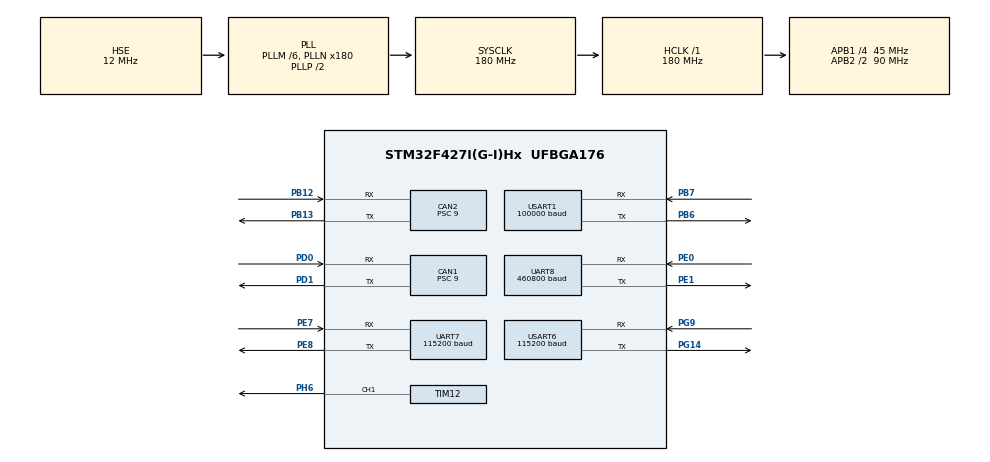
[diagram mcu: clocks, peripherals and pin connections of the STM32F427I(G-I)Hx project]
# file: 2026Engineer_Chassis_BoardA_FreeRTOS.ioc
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CAN1.BS1=CAN_BS1_2TQ
CAN1.BS2=CAN_BS2_2TQ
CAN1.CalculateBaudRate=1000000
CAN1.CalculateTimeBit=1000
CAN1.CalculateTimeQuantum=200.0
CAN1.NART=ENABLE
CAN1.Prescaler=9
CAN2.BS1=CAN_BS1_2TQ
CAN2.BS2=CAN_BS2_2TQ
CAN2.CalculateBaudRate=1000000
CAN2.CalculateTimeBit=1000
CAN2.CalculateTimeQuantum=200.0
CAN2.Prescaler=9
Dma.Request0=USART1_RX
Dma.Request1=USART1_TX
Dma.Request2=USART6_RX
Dma.Request3=USART6_TX
Dma.Request4=UART7_RX
Dma.Request5=UART7_TX
Dma.UART7_RX.4.Direction=DMA_PERIPH_TO_MEMORY
Dma.UART7_RX.4.FIFOMode=DMA_FIFOMODE_DISABLE
Dma.UART7_RX.4.Instance=DMA1_Stream3
Dma.UART7_RX.4.MemDataAlignment=DMA_MDATAALIGN_BYTE
Dma.UART7_RX.4.MemInc=DMA_MINC_ENABLE
Dma.UART7_RX.4.Mode=DMA_NORMAL
Dma.UART7_RX.4.PeriphDataAlignment=DMA_PDATAALIGN_BYTE
Dma.UART7_RX.4.PeriphInc=DMA_PINC_DISABLE
Dma.UART7_RX.4.Priority=DMA_PRIORITY_LOW
Dma.UART7_TX.5.Direction=DMA_MEMORY_TO_PERIPH
Dma.UART7_TX.5.FIFOMode=DMA_FIFOMODE_DISABLE
Dma.UART7_TX.5.Instance=DMA1_Stream1
Dma.UART7_TX.5.MemDataAlignment=DMA_MDATAALIGN_BYTE
Dma.UART7_TX.5.MemInc=DMA_MINC_ENABLE
Dma.UART7_TX.5.Mode=DMA_NORMAL
Dma.UART7_TX.5.PeriphDataAlignment=DMA_PDATAALIGN_BYTE
Dma.UART7_TX.5.PeriphInc=DMA_PINC_DISABLE
Dma.UART7_TX.5.Priority=DMA_PRIORITY_LOW
Dma.USART1_RX.0.Direction=DMA_PERIPH_TO_MEMORY
Dma.USART1_RX.0.FIFOMode=DMA_FIFOMODE_DISABLE
Dma.USART1_RX.0.Instance=DMA2_Stream2
Dma.USART1_RX.0.MemDataAlignment=DMA_MDATAALIGN_BYTE
Dma.USART1_RX.0.MemInc=DMA_MINC_ENABLE
Dma.USART1_RX.0.Mode=DMA_NORMAL
Dma.USART1_RX.0.PeriphDataAlignment=DMA_PDATAALIGN_BYTE
Dma.USART1_RX.0.PeriphInc=DMA_PINC_DISABLE
Dma.USART1_RX.0.Priority=DMA_PRIORITY_LOW
Dma.USART1_TX.1.Direction=DMA_MEMORY_TO_PERIPH
Dma.USART1_TX.1.FIFOMode=DMA_FIFOMODE_DISABLE
Dma.USART1_TX.1.Instance=DMA2_Stream7
Dma.USART1_TX.1.MemDataAlignment=DMA_MDATAALIGN_BYTE
Dma.USART1_TX.1.MemInc=DMA_MINC_ENABLE
Dma.USART1_TX.1.Mode=DMA_NORMAL
Dma.USART1_TX.1.PeriphDataAlignment=DMA_PDATAALIGN_BYTE
Dma.USART1_TX.1.PeriphInc=DMA_PINC_DISABLE
Dma.USART1_TX.1.Priority=DMA_PRIORITY_LOW
Dma.USART6_RX.2.Direction=DMA_PERIPH_TO_MEMORY
Dma.USART6_RX.2.FIFOMode=DMA_FIFOMODE_DISABLE
Dma.USART6_RX.2.Instance=DMA2_Stream1
Dma.USART6_RX.2.MemDataAlignment=DMA_MDATAALIGN_BYTE
Dma.USART6_RX.2.MemInc=DMA_MINC_ENABLE
Dma.USART6_RX.2.Mode=DMA_NORMAL
Dma.USART6_RX.2.PeriphDataAlignment=DMA_PDATAALIGN_BYTE
Dma.USART6_RX.2.PeriphInc=DMA_PINC_DISABLE
Dma.USART6_RX.2.Priority=DMA_PRIORITY_LOW
Dma.USART6_TX.3.Direction=DMA_MEMORY_TO_PERIPH
Dma.USART6_TX.3.FIFOMode=DMA_FIFOMODE_DISABLE
Dma.USART6_TX.3.Instance=DMA2_Stream6
Dma.USART6_TX.3.MemDataAlignment=DMA_MDATAALIGN_BYTE
Dma.USART6_TX.3.MemInc=DMA_MINC_ENABLE
Dma.USART6_TX.3.Mode=DMA_NORMAL
Dma.USART6_TX.3.PeriphDataAlignment=DMA_PDATAALIGN_BYTE
Dma.USART6_TX.3.PeriphInc=DMA_PINC_DISABLE
Dma.USART6_TX.3.Priority=DMA_PRIORITY_LOW
FREERTOS.Tasks01=defaultTask,24,128,StartDefaultTask,Default,NULL,Dynamic,NULL,NULL;motortask,48,512,MotorTask,As external,NULL,Dynamic,NULL,NULL;chassistask,49,512,ChassisTask,As external,NULL,Dynamic,NULL,NULL;remotetask,46,512,RemoteTask,As external,NULL,Dynamic,NULL,NULL;refereetask,47,512,RefereeTask,As external,NULL,Dynamic,NULL,NULL;communication,45,512,CommunicationTask,As external,NULL,Dynamic,NULL,NULL
Mcu.Family=STM32F4
Mcu.Name=STM32F427I(G-I)Hx
Mcu.Package=UFBGA176
NVIC.CAN1_RX0_IRQn=true\:5\:0\:false\:false\:true\:true\:true\:true\:true
NVIC.CAN1_RX1_IRQn=true\:5\:0\:false\:false\:true\:true\:true\:true\:true
NVIC.CAN1_TX_IRQn=true\:5\:0\:false\:false\:true\:true\:true\:true\:true
NVIC.CAN2_RX0_IRQn=true\:5\:0\:false\:false\:true\:true\:true\:true\:true
NVIC.CAN2_TX_IRQn=true\:5\:0\:false\:false\:true\:true\:true\:true\:true
NVIC.DMA1_Stream1_IRQn=true\:5\:0\:false\:false\:true\:true\:false\:true\:true
NVIC.DMA1_Stream3_IRQn=true\:5\:0\:false\:false\:true\:true\:false\:true\:true
NVIC.DMA2_Stream1_IRQn=true\:5\:0\:false\:false\:true\:true\:false\:true\:true
NVIC.DMA2_Stream2_IRQn=true\:5\:0\:false\:false\:true\:true\:false\:true\:true
NVIC.DMA2_Stream6_IRQn=true\:5\:0\:false\:false\:true\:true\:false\:true\:true
NVIC.DMA2_Stream7_IRQn=true\:5\:0\:false\:false\:true\:true\:false\:true\:true
NVIC.PriorityGroup=NVIC_PRIORITYGROUP_4
NVIC.TIM7_IRQn=true\:15\:0\:false\:false\:true\:false\:false\:true\:true
NVIC.TIM8_BRK_TIM12_IRQn=true\:5\:0\:false\:false\:true\:true\:true\:true\:true
NVIC.TimeBase=TIM7_IRQn
NVIC.TimeBaseIP=TIM7
NVIC.UART7_IRQn=true\:5\:0\:false\:false\:true\:true\:true\:true\:true
NVIC.UART8_IRQn=true\:5\:0\:false\:false\:true\:true\:true\:true\:true
NVIC.USART1_IRQn=true\:5\:0\:false\:false\:true\:true\:true\:true\:true
NVIC.USART6_IRQn=true\:5\:0\:false\:false\:true\:true\:true\:true\:true
PA13.Mode=Serial_Wire
PA13.Signal=SYS_JTMS-SWDIO
PA14.Mode=Serial_Wire
PA14.Signal=SYS_JTCK-SWCLK
PB12.Mode=CAN_Activate
PB12.Signal=CAN2_RX
PB13.Mode=CAN_Activate
PB13.Signal=CAN2_TX
PB6.Mode=Asynchronous
PB6.Signal=USART1_TX
PB7.Mode=Asynchronous
PB7.Signal=USART1_RX
PD0.Mode=CAN_Activate
PD0.Signal=CAN1_RX
PD1.Mode=CAN_Activate
PD1.Signal=CAN1_TX
PE0.Mode=Asynchronous
PE0.Signal=UART8_RX
PE1.Mode=Asynchronous
PE1.Signal=UART8_TX
PE7.Mode=Asynchronous
PE7.Signal=UART7_RX
PE8.Mode=Asynchronous
PE8.Signal=UART7_TX
PG14.Mode=Asynchronous
PG14.Signal=USART6_TX
PG9.Mode=Asynchronous
PG9.Signal=USART6_RX
PH0/OSC_IN.Mode=HSE-External-Oscillator
PH0/OSC_IN.Signal=RCC_OSC_IN
PH1/OSC_OUT.Mode=HSE-External-Oscillator
PH1/OSC_OUT.Signal=RCC_OSC_OUT
PH6.Signal=S_TIM12_CH1
ProjectManager.HeapSize=0x200
ProjectManager.StackSize=0x400
ProjectManager.TargetToolchain=MDK-ARM V5.32
RCC.48MHZClocksFreq_Value=90000000
RCC.AHBFreq_Value=180000000
RCC.APB1CLKDivider=RCC_HCLK_DIV4
RCC.APB1Freq_Value=45000000
RCC.APB1TimFreq_Value=90000000
RCC.APB2CLKDivider=RCC_HCLK_DIV2
RCC.APB2Freq_Value=90000000
RCC.APB2TimFreq_Value=180000000
RCC.CortexFreq_Value=180000000
RCC.HCLKFreq_Value=180000000
RCC.HSE_VALUE=12000000
RCC.HSI_VALUE=16000000
RCC.LSE_VALUE=32768
RCC.PLLM=6
RCC.PLLN=180
RCC.PLLSourceVirtual=RCC_PLLSOURCE_HSE
RCC.SYSCLKFreq_VALUE=180000000
RCC.SYSCLKSource=RCC_SYSCLKSOURCE_PLLCLK
RCC.VCOOutputFreq_Value=360000000
SH.S_TIM12_CH1.0=TIM12_CH1,PWM Generation1 CH1
TIM12.Channel-PWM\ Generation1\ CH1=TIM_CHANNEL_1
TIM12.Period=400-1
TIM12.Prescaler=180-1
UART7.BaudRate=115200
UART7.VirtualMode=Asynchronous
UART8.BaudRate=460800
UART8.VirtualMode=Asynchronous
USART1.BaudRate=100000
USART1.Parity=PARITY_EVEN
USART1.VirtualMode=VM_ASYNC
USART1.WordLength=WORDLENGTH_9B
USART6.BaudRate=115200
USART6.VirtualMode=VM_ASYNC
VP_FREERTOS_VS_CMSIS_V2.Mode=CMSIS_V2
VP_SYS_VS_tim7.Mode=TIM7
board=custom

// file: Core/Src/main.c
/* USER CODE BEGIN Header */
/**
  ******************************************************************************
  * @file           : main.c
  * @brief          : Main program body
  ******************************************************************************
  * @attention
  *
  * Copyright (c) 2025 STMicroelectronics.
  * All rights reserved.
  *
  * This software is licensed under terms that can be found in the LICENSE file
  * in the root directory of this software component.
  * If no LICENSE file comes with this software, it is provided AS-IS.
  *
  ******************************************************************************
  */
/* USER CODE END Header */
#include "main.h"
#include "cmsis_os.h"
#include "can.h"
#include "dma.h"
#include "tim.h"
#include "usart.h"
#include "gpio.h"

void SystemClock_Config(void);
void MX_FREERTOS_Init(void);

int main(void)
{

  /* MCU Configuration--------------------------------------------------------*/

  /* Reset of all peripherals, Initializes the Flash interface and the Systick. */
  HAL_Init();

  /* Configure the system clock */
  SystemClock_Config();

  /* Initialize all configured peripherals */
  MX_GPIO_Init();
  MX_DMA_Init();
  MX_CAN1_Init();
  MX_CAN2_Init();
  MX_USART1_UART_Init();
  MX_TIM12_Init();
  MX_USART6_UART_Init();
  MX_UART7_Init();
  MX_UART8_Init();
  /* USER CODE BEGIN 2 */
  HAL_TIM_Base_Start_IT(&htim12);
  HAL_TIM_PWM_Start(&htim12, TIM_CHANNEL_1);
  /* USER CODE END 2 */

  /* Init scheduler */
  osKernelInitialize();  /* Call init function for freertos objects (in cmsis_os2.c) */
  MX_FREERTOS_Init();

  /* Start scheduler */
  osKernelStart();

  /* We should never get here as control is now taken by the scheduler */

  /* Infinite loop */
  while (1)
  {

  }
}

void SystemClock_Config(void)
{
  RCC_OscInitTypeDef RCC_OscInitStruct = {0};
  RCC_ClkInitTypeDef RCC_ClkInitStruct = {0};

  /** Configure the main internal regulator output voltage
  */
  __HAL_RCC_PWR_CLK_ENABLE();
  __HAL_PWR_VOLTAGESCALING_CONFIG(PWR_REGULATOR_VOLTAGE_SCALE1);

  /** Initializes the RCC Oscillators according to the specified parameters
  * in the RCC_OscInitTypeDef structure.
  */
  RCC_OscInitStruct.OscillatorType = RCC_OSCILLATORTYPE_HSE;
  RCC_OscInitStruct.HSEState = RCC_HSE_ON;
  RCC_OscInitStruct.PLL.PLLState = RCC_PLL_ON;
  RCC_OscInitStruct.PLL.PLLSource = RCC_PLLSOURCE_HSE;
  RCC_OscInitStruct.PLL.PLLM = 6;
  RCC_OscInitStruct.PLL.PLLN = 180;
  RCC_OscInitStruct.PLL.PLLP = RCC_PLLP_DIV2;
  RCC_OscInitStruct.PLL.PLLQ = 4;
  if (HAL_RCC_OscConfig(&RCC_OscInitStruct) != HAL_OK)
  {
    Error_Handler();
  }

  /** Activate the Over-Drive mode
  */
  if (HAL_PWREx_EnableOverDrive() != HAL_OK)
  {
    Error_Handler();
  }

  /** Initializes the CPU, AHB and APB buses clocks
  */
  RCC_ClkInitStruct.ClockType = RCC_CLOCKTYPE_HCLK|RCC_CLOCKTYPE_SYSCLK
                              |RCC_CLOCKTYPE_PCLK1|RCC_CLOCKTYPE_PCLK2;
  RCC_ClkInitStruct.SYSCLKSource = RCC_SYSCLKSOURCE_PLLCLK;
  RCC_ClkInitStruct.AHBCLKDivider = RCC_SYSCLK_DIV1;
  RCC_ClkInitStruct.APB1CLKDivider = RCC_HCLK_DIV4;
  RCC_ClkInitStruct.APB2CLKDivider = RCC_HCLK_DIV2;

  if (HAL_RCC_ClockConfig(&RCC_ClkInitStruct, FLASH_LATENCY_5) != HAL_OK)
  {
    Error_Handler();
  }
}

void HAL_TIM_PeriodElapsedCallback(TIM_HandleTypeDef *htim)
{
  if (htim->Instance == TIM7)
  {
    HAL_IncTick();
  }
}

void Error_Handler(void)
{
  __disable_irq();
  while (1)
  {
  }
}

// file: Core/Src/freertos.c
/* USER CODE BEGIN Header */
/**
  ******************************************************************************
  * File Name          : freertos.c
  * Description        : Code for freertos applications
  ******************************************************************************
  * @attention
  *
  * Copyright (c) 2025 STMicroelectronics.
  * All rights reserved.
  *
  * This software is licensed under terms that can be found in the LICENSE file
  * in the root directory of this software component.
  * If no LICENSE file comes with this software, it is provided AS-IS.
  *
  ******************************************************************************
  */
/* USER CODE END Header */

#include "FreeRTOS.h"
#include "task.h"
#include "main.h"
#include "cmsis_os.h"

/* Definitions for defaultTask */
osThreadId_t defaultTaskHandle;
const osThreadAttr_t defaultTask_attributes = {
  .name = "defaultTask",
  .stack_size = 128 * 4,
  .priority = (osPriority_t) osPriorityNormal,
};
/* Definitions for motortask */
osThreadId_t motortaskHandle;
const osThreadAttr_t motortask_attributes = {
  .name = "motortask",
  .stack_size = 512 * 4,
  .priority = (osPriority_t) osPriorityRealtime,
};
/* Definitions for chassistask */
osThreadId_t chassistaskHandle;
const osThreadAttr_t chassistask_attributes = {
  .name = "chassistask",
  .stack_size = 512 * 4,
  .priority = (osPriority_t) osPriorityRealtime1,
};
/* Definitions for remotetask */
osThreadId_t remotetaskHandle;
const osThreadAttr_t remotetask_attributes = {
  .name = "remotetask",
  .stack_size = 512 * 4,
  .priority = (osPriority_t) osPriorityHigh6,
};
/* Definitions for refereetask */
osThreadId_t refereetaskHandle;
const osThreadAttr_t refereetask_attributes = {
  .name = "refereetask",
  .stack_size = 512 * 4,
  .priority = (osPriority_t) osPriorityHigh7,
};
/* Definitions for communication */
osThreadId_t communicationHandle;
const osThreadAttr_t communication_attributes = {
  .name = "communication",
  .stack_size = 512 * 4,
  .priority = (osPriority_t) osPriorityHigh5,
};

void StartDefaultTask(void *argument);
extern void MotorTask(void *argument);
extern void ChassisTask(void *argument);
extern void RemoteTask(void *argument);
extern void RefereeTask(void *argument);
extern void CommunicationTask(void *argument);

void MX_FREERTOS_Init(void); /* (MISRA C 2004 rule 8.1) */

void MX_FREERTOS_Init(void) {

  /* Create the thread(s) */
  /* creation of defaultTask */
  defaultTaskHandle = osThreadNew(StartDefaultTask, NULL, &defaultTask_attributes);

  /* creation of motortask */
  motortaskHandle = osThreadNew(MotorTask, NULL, &motortask_attributes);

  /* creation of chassistask */
  chassistaskHandle = osThreadNew(ChassisTask, NULL, &chassistask_attributes);

  /* creation of remotetask */
  remotetaskHandle = osThreadNew(RemoteTask, NULL, &remotetask_attributes);

  /* creation of refereetask */
  refereetaskHandle = osThreadNew(RefereeTask, NULL, &refereetask_attributes);

  /* creation of communication */
  communicationHandle = osThreadNew(CommunicationTask, NULL, &communication_attributes);

}

void StartDefaultTask(void *argument)
{
  for(;;)
  {
    osDelay(1);
  }
}
